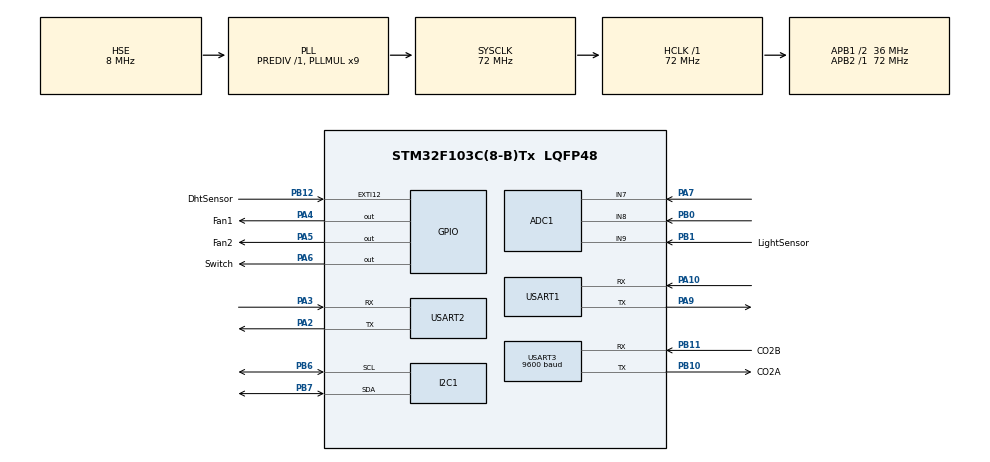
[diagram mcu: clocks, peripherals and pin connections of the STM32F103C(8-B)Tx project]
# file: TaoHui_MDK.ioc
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ADC1.Channel-1\#ChannelRegularConversion=ADC_CHANNEL_7
ADC1.Channel-2\#ChannelRegularConversion=ADC_CHANNEL_8
ADC1.Channel-3\#ChannelRegularConversion=ADC_CHANNEL_9
ADC1.NbrOfConversion=3
ADC1.NbrOfConversionFlag=1
ADC1.Rank-1\#ChannelRegularConversion=1
ADC1.Rank-2\#ChannelRegularConversion=2
ADC1.Rank-3\#ChannelRegularConversion=3
ADC1.SamplingTime-1\#ChannelRegularConversion=ADC_SAMPLETIME_239CYCLES_5
ADC1.SamplingTime-2\#ChannelRegularConversion=ADC_SAMPLETIME_239CYCLES_5
ADC1.SamplingTime-3\#ChannelRegularConversion=ADC_SAMPLETIME_239CYCLES_5
ADC1.master=1
Dma.ADC1.0.Direction=DMA_PERIPH_TO_MEMORY
Dma.ADC1.0.Instance=DMA1_Channel1
Dma.ADC1.0.MemDataAlignment=DMA_MDATAALIGN_HALFWORD
Dma.ADC1.0.MemInc=DMA_MINC_ENABLE
Dma.ADC1.0.Mode=DMA_NORMAL
Dma.ADC1.0.PeriphDataAlignment=DMA_PDATAALIGN_HALFWORD
Dma.ADC1.0.PeriphInc=DMA_PINC_DISABLE
Dma.ADC1.0.Priority=DMA_PRIORITY_LOW
Dma.Request0=ADC1
Dma.Request1=USART3_RX
Dma.USART3_RX.1.Direction=DMA_PERIPH_TO_MEMORY
Dma.USART3_RX.1.Instance=DMA1_Channel3
Dma.USART3_RX.1.MemDataAlignment=DMA_MDATAALIGN_BYTE
Dma.USART3_RX.1.MemInc=DMA_MINC_ENABLE
Dma.USART3_RX.1.Mode=DMA_CIRCULAR
Dma.USART3_RX.1.PeriphDataAlignment=DMA_PDATAALIGN_BYTE
Dma.USART3_RX.1.PeriphInc=DMA_PINC_DISABLE
Dma.USART3_RX.1.Priority=DMA_PRIORITY_LOW
FREERTOS.Tasks01=Task_CLI,24,256,Task_CLI_Handler,As weak,NULL,Dynamic,NULL,NULL;Task_ESP,8,512,Task_ESP_Handler,As weak,NULL,Dynamic,NULL,NULL;Task_Sensor,8,256,Task_Sensor_Handler,As weak,NULL,Dynamic,NULL,NULL;Task_Control,8,256,Task_Control_Handler,As weak,NULL,Dynamic,NULL,NULL;Task_Display,8,256,Task_Display_Handler,As weak,NULL,Dynamic,NULL,NULL
FREERTOS.configTOTAL_HEAP_SIZE=8192
FREERTOS.configUSE_NEWLIB_REENTRANT=0
I2C1.I2C_Mode=I2C_Fast
Mcu.Family=STM32F1
Mcu.Name=STM32F103C(8-B)Tx
Mcu.Package=LQFP48
NVIC.DMA1_Channel1_IRQn=true\:5\:0\:false\:false\:true\:true\:false\:true\:true
NVIC.DMA1_Channel3_IRQn=true\:5\:0\:false\:false\:true\:true\:false\:true\:true
NVIC.EXTI15_10_IRQn=true\:5\:0\:true\:false\:true\:true\:true\:true\:true
NVIC.PriorityGroup=NVIC_PRIORITYGROUP_4
NVIC.TIM4_IRQn=true\:15\:0\:false\:false\:true\:false\:false\:true\:true
NVIC.TimeBase=TIM4_IRQn
NVIC.TimeBaseIP=TIM4
NVIC.USART3_IRQn=true\:5\:0\:false\:false\:true\:true\:true\:true\:true
PA10.Mode=Asynchronous
PA10.Signal=USART1_RX
PA13.Mode=Serial_Wire
PA13.Signal=SYS_JTMS-SWDIO
PA14.Mode=Serial_Wire
PA14.Signal=SYS_JTCK-SWCLK
PA2.Mode=Asynchronous
PA2.Signal=USART2_TX
PA3.Mode=Asynchronous
PA3.Signal=USART2_RX
PA4.GPIO_Label=Fan1
PA4.Signal=GPIO_Output
PA5.GPIO_Label=Fan2
PA5.Signal=GPIO_Output
PA6.GPIO_Label=Switch
PA6.Signal=GPIO_Output
PA7.Signal=ADCx_IN7
PA9.Mode=Asynchronous
PA9.Signal=USART1_TX
PB0.Signal=ADCx_IN8
PB1.GPIO_Label=LightSensor
PB1.Signal=ADCx_IN9
PB10.GPIO_Label=CO2A
PB10.Mode=Asynchronous
PB10.Signal=USART3_TX
PB11.GPIO_Label=CO2B
PB11.Mode=Asynchronous
PB11.Signal=USART3_RX
PB12.GPIO_Label=DhtSensor
PB12.GPIO_ModeDefaultEXTI=GPIO_MODE_IT_FALLING
PB12.GPIO_PuPd=GPIO_PULLUP
PB12.Signal=GPXTI12
PB6.Mode=I2C
PB6.Signal=I2C1_SCL
PB7.Mode=I2C
PB7.Signal=I2C1_SDA
PD0-OSC_IN.Mode=HSE-External-Oscillator
PD0-OSC_IN.Signal=RCC_OSC_IN
PD1-OSC_OUT.Mode=HSE-External-Oscillator
PD1-OSC_OUT.Signal=RCC_OSC_OUT
ProjectManager.HeapSize=0x400
ProjectManager.StackSize=0x600
ProjectManager.TargetToolchain=MDK-ARM V5.32
RCC.ADCPresc=RCC_ADCPCLK2_DIV6
RCC.AHBFreq_Value=72000000
RCC.APB1CLKDivider=RCC_HCLK_DIV2
RCC.APB1Freq_Value=36000000
RCC.APB1TimFreq_Value=72000000
RCC.APB2Freq_Value=72000000
RCC.APB2TimFreq_Value=72000000
RCC.HCLKFreq_Value=72000000
RCC.PLLMUL=RCC_PLL_MUL9
RCC.PLLSourceVirtual=RCC_PLLSOURCE_HSE
RCC.SYSCLKFreq_VALUE=72000000
RCC.SYSCLKSource=RCC_SYSCLKSOURCE_PLLCLK
RCC.USBFreq_Value=72000000
SH.ADCx_IN7.0=ADC1_IN7,IN7
SH.ADCx_IN8.0=ADC1_IN8,IN8
SH.ADCx_IN9.0=ADC1_IN9,IN9
TIM2.AutoReloadPreload=TIM_AUTORELOAD_PRELOAD_ENABLE
TIM2.Prescaler=72-1
USART1.VirtualMode=VM_ASYNC
USART2.VirtualMode=VM_ASYNC
USART3.BaudRate=9600
USART3.VirtualMode=VM_ASYNC
VP_FREERTOS_VS_CMSIS_V2.Mode=CMSIS_V2
VP_SYS_VS_tim4.Mode=TIM4
VP_TIM2_VS_ClockSourceINT.Mode=Internal
board=custom

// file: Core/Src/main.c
/* USER CODE BEGIN Header */
/**
  ******************************************************************************
  * @file           : main.c
  * @brief          : Main program body
  ******************************************************************************
  * @attention
  *
  * Copyright (c) 2026 STMicroelectronics.
  * All rights reserved.
  *
  * This software is licensed under terms that can be found in the LICENSE file
  * in the root directory of this software component.
  * If no LICENSE file comes with this software, it is provided AS-IS.
  *
  ******************************************************************************
  */
/* USER CODE END Header */
#include "main.h"
#include "cmsis_os.h"
#include "adc.h"
#include "dma.h"
#include "i2c.h"
#include "tim.h"
#include "usart.h"
#include "gpio.h"

/* USER CODE BEGIN PV */
volatile SystemDataSet_t g_sys_data;
/* USER CODE END PV */

void SystemClock_Config(void);
void MX_FREERTOS_Init(void);

int main(void)
{

  /* MCU Configuration--------------------------------------------------------*/

  /* Reset of all peripherals, Initializes the Flash interface and the Systick. */
  HAL_Init();

  /* Configure the system clock */
  SystemClock_Config();

  /* Initialize all configured peripherals */
  MX_GPIO_Init();
  MX_DMA_Init();
  MX_I2C1_Init();
  MX_USART1_UART_Init();
  MX_USART2_UART_Init();
  MX_ADC1_Init();
  MX_TIM2_Init();
  MX_USART3_UART_Init();

  /* Init scheduler */
  osKernelInitialize();  /* Call init function for freertos objects (in freertos.c) */
  MX_FREERTOS_Init();

  /* Start scheduler */
  osKernelStart();
  /* We should never get here as control is now taken by the scheduler */
  /* Infinite loop */
  while (1)
  {

  }
}

void SystemClock_Config(void)
{
  RCC_OscInitTypeDef RCC_OscInitStruct = {0};
  RCC_ClkInitTypeDef RCC_ClkInitStruct = {0};
  RCC_PeriphCLKInitTypeDef PeriphClkInit = {0};

  /** Initializes the RCC Oscillators according to the specified parameters
  * in the RCC_OscInitTypeDef structure.
  */
  RCC_OscInitStruct.OscillatorType = RCC_OSCILLATORTYPE_HSE;
  RCC_OscInitStruct.HSEState = RCC_HSE_ON;
  RCC_OscInitStruct.HSEPredivValue = RCC_HSE_PREDIV_DIV1;
  RCC_OscInitStruct.HSIState = RCC_HSI_ON;
  RCC_OscInitStruct.PLL.PLLState = RCC_PLL_ON;
  RCC_OscInitStruct.PLL.PLLSource = RCC_PLLSOURCE_HSE;
  RCC_OscInitStruct.PLL.PLLMUL = RCC_PLL_MUL9;
  if (HAL_RCC_OscConfig(&RCC_OscInitStruct) != HAL_OK)
  {
    Error_Handler();
  }

  /** Initializes the CPU, AHB and APB buses clocks
  */
  RCC_ClkInitStruct.ClockType = RCC_CLOCKTYPE_HCLK|RCC_CLOCKTYPE_SYSCLK
                              |RCC_CLOCKTYPE_PCLK1|RCC_CLOCKTYPE_PCLK2;
  RCC_ClkInitStruct.SYSCLKSource = RCC_SYSCLKSOURCE_PLLCLK;
  RCC_ClkInitStruct.AHBCLKDivider = RCC_SYSCLK_DIV1;
  RCC_ClkInitStruct.APB1CLKDivider = RCC_HCLK_DIV2;
  RCC_ClkInitStruct.APB2CLKDivider = RCC_HCLK_DIV1;

  if (HAL_RCC_ClockConfig(&RCC_ClkInitStruct, FLASH_LATENCY_2) != HAL_OK)
  {
    Error_Handler();
  }
  PeriphClkInit.PeriphClockSelection = RCC_PERIPHCLK_ADC;
  PeriphClkInit.AdcClockSelection = RCC_ADCPCLK2_DIV6;
  if (HAL_RCCEx_PeriphCLKConfig(&PeriphClkInit) != HAL_OK)
  {
    Error_Handler();
  }
}

void HAL_TIM_PeriodElapsedCallback(TIM_HandleTypeDef *htim)
{
  if (htim->Instance == TIM4) {
    HAL_IncTick();
  }
}

void Error_Handler(void)
{
  __disable_irq();
  while (1)
  {
  }
}

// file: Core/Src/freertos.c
/* USER CODE BEGIN Header */
/**
  ******************************************************************************
  * File Name          : freertos.c
  * Description        : Code for freertos applications
  ******************************************************************************
  * @attention
  *
  * Copyright (c) 2026 STMicroelectronics.
  * All rights reserved.
  *
  * This software is licensed under terms that can be found in the LICENSE file
  * in the root directory of this software component.
  * If no LICENSE file comes with this software, it is provided AS-IS.
  *
  ******************************************************************************
  */
/* USER CODE END Header */

#include "FreeRTOS.h"
#include "task.h"
#include "main.h"
#include "cmsis_os.h"

/* Definitions for Task_CLI */
osThreadId_t Task_CLIHandle;
const osThreadAttr_t Task_CLI_attributes = {
  .name = "Task_CLI",
  .stack_size = 256 * 4,
  .priority = (osPriority_t) osPriorityNormal,
};
/* Definitions for Task_ESP */
osThreadId_t Task_ESPHandle;
const osThreadAttr_t Task_ESP_attributes = {
  .name = "Task_ESP",
  .stack_size = 512 * 4,
  .priority = (osPriority_t) osPriorityLow,
};
/* Definitions for Task_Sensor */
osThreadId_t Task_SensorHandle;
const osThreadAttr_t Task_Sensor_attributes = {
  .name = "Task_Sensor",
  .stack_size = 256 * 4,
  .priority = (osPriority_t) osPriorityLow,
};
/* Definitions for Task_Control */
osThreadId_t Task_ControlHandle;
const osThreadAttr_t Task_Control_attributes = {
  .name = "Task_Control",
  .stack_size = 256 * 4,
  .priority = (osPriority_t) osPriorityLow,
};
/* Definitions for Task_Display */
osThreadId_t Task_DisplayHandle;
const osThreadAttr_t Task_Display_attributes = {
  .name = "Task_Display",
  .stack_size = 256 * 4,
  .priority = (osPriority_t) osPriorityLow,
};

void Task_CLI_Handler(void *argument);
void Task_ESP_Handler(void *argument);
void Task_Sensor_Handler(void *argument);
void Task_Control_Handler(void *argument);
void Task_Display_Handler(void *argument);

void MX_FREERTOS_Init(void); /* (MISRA C 2004 rule 8.1) */

void MX_FREERTOS_Init(void) {

  /* Create the thread(s) */
  /* creation of Task_CLI */
  Task_CLIHandle = osThreadNew(Task_CLI_Handler, NULL, &Task_CLI_attributes);

  /* creation of Task_ESP */
  Task_ESPHandle = osThreadNew(Task_ESP_Handler, NULL, &Task_ESP_attributes);

  /* creation of Task_Sensor */
  Task_SensorHandle = osThreadNew(Task_Sensor_Handler, NULL, &Task_Sensor_attributes);

  /* creation of Task_Control */
  Task_ControlHandle = osThreadNew(Task_Control_Handler, NULL, &Task_Control_attributes);

  /* creation of Task_Display */
  Task_DisplayHandle = osThreadNew(Task_Display_Handler, NULL, &Task_Display_attributes);

}

__weak void Task_CLI_Handler(void *argument)
{
  for(;;)
  {
    osDelay(1);
  }
}

__weak void Task_ESP_Handler(void *argument)
{
  for(;;)
  {
    osDelay(1);
  }
}

__weak void Task_Sensor_Handler(void *argument)
{
  for(;;)
  {
    osDelay(1);
  }
}

__weak void Task_Control_Handler(void *argument)
{
  for(;;)
  {
    osDelay(1);
  }
}

__weak void Task_Display_Handler(void *argument)
{
  for(;;)
  {
    osDelay(1);
  }
}
